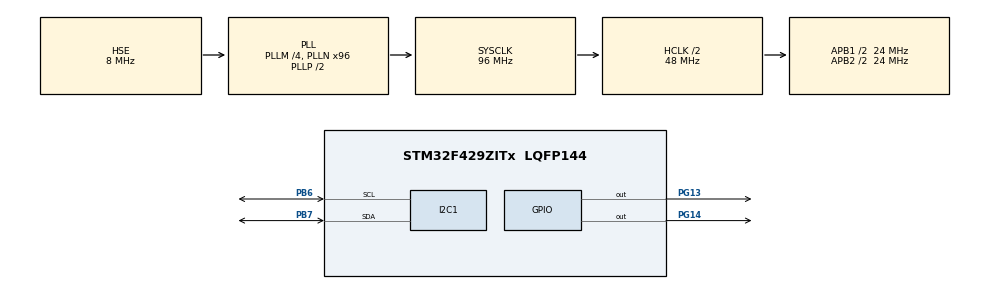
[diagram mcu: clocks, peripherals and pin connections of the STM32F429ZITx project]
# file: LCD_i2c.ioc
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Mcu.Family=STM32F4
Mcu.Name=STM32F429ZITx
Mcu.Package=LQFP144
NVIC.PriorityGroup=NVIC_PRIORITYGROUP_0
NVIC.TIM3_IRQn=true\:0\:0\:false\:false\:true\:true\:true\:true
NVIC.TIM4_IRQn=true\:0\:0\:false\:false\:true\:true\:true\:true
PA13.Mode=Serial_Wire
PA13.Signal=SYS_JTMS-SWDIO
PA14.Mode=Serial_Wire
PA14.Signal=SYS_JTCK-SWCLK
PB6.GPIO_Pu=GPIO_NOPULL
PB6.GPIO_Speed=GPIO_SPEED_FREQ_HIGH
PB6.Mode=I2C
PB6.Signal=I2C1_SCL
PB7.GPIO_Pu=GPIO_NOPULL
PB7.GPIO_Speed=GPIO_SPEED_FREQ_HIGH
PB7.Mode=I2C
PB7.Signal=I2C1_SDA
PG13.PinState=GPIO_PIN_SET
PG13.Signal=GPIO_Output
PG14.Signal=GPIO_Output
PH0/OSC_IN.Mode=HSE-External-Oscillator
PH0/OSC_IN.Signal=RCC_OSC_IN
PH1/OSC_OUT.Mode=HSE-External-Oscillator
PH1/OSC_OUT.Signal=RCC_OSC_OUT
ProjectManager.HeapSize=0x200
ProjectManager.StackSize=0x400
ProjectManager.TargetToolchain=Makefile
RCC.48MHZClocksFreq_Value=64000000
RCC.AHBCLKDivider=RCC_SYSCLK_DIV2
RCC.AHBFreq_Value=48000000
RCC.APB1CLKDivider=RCC_HCLK_DIV2
RCC.APB1Freq_Value=24000000
RCC.APB1TimFreq_Value=48000000
RCC.APB2CLKDivider=RCC_HCLK_DIV2
RCC.APB2Freq_Value=24000000
RCC.APB2TimFreq_Value=48000000
RCC.CortexFreq_Value=48000000
RCC.HCLKFreq_Value=48000000
RCC.HSE_VALUE=8000000
RCC.HSI_VALUE=16000000
RCC.LSE_VALUE=32768
RCC.PLLM=4
RCC.PLLN=96
RCC.PLLQ=3
RCC.PLLSourceVirtual=RCC_PLLSOURCE_HSE
RCC.RCC_TIM_PRescaler_Selection=RCC_TIMPRES_DESACTIVATED
RCC.SYSCLKFreq_VALUE=96000000
RCC.SYSCLKSource=RCC_SYSCLKSOURCE_PLLCLK
RCC.VCOOutputFreq_Value=192000000
TIM3.ClockDivision=TIM_CLOCKDIVISION_DIV4
TIM3.Period=99
TIM3.Prescaler=199
TIM4.ClockDivision=TIM_CLOCKDIVISION_DIV4
TIM4.Period=999
TIM4.Prescaler=199
VP_TIM3_VS_ClockSourceINT.Mode=Internal
VP_TIM4_VS_ClockSourceINT.Mode=Internal
board=STM32F429I-DISC1

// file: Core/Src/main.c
/* USER CODE BEGIN Header */
/**
  ******************************************************************************
  * @file           : main.c
  * @brief          : Main program body
  ******************************************************************************
  * @attention
  *
  * Copyright (c) 2024 STMicroelectronics.
  * All rights reserved.
  *
  * This software is licensed under terms that can be found in the LICENSE file
  * in the root directory of this software component.
  * If no LICENSE file comes with this software, it is provided AS-IS.
  *
  ******************************************************************************
  */
/* USER CODE END Header */
#include "main.h"
#include "i2c.h"
#include "tim.h"
#include "gpio.h"

/* USER CODE BEGIN Includes */
#include "lcd.h"
/* USER CODE END Includes */

void SystemClock_Config(void);

int main(void)
{

  /* MCU Configuration--------------------------------------------------------*/

  /* Reset of all peripherals, Initializes the Flash interface and the Systick. */
  HAL_Init();

  /* Configure the system clock */
  SystemClock_Config();

  /* Initialize all configured peripherals */
  MX_GPIO_Init();
  MX_TIM3_Init();
  MX_TIM4_Init();
  MX_I2C1_Init();
  /* USER CODE BEGIN 2 */
  LCDInit();
  LCDSendString("HELLO WORLD",0,0);
  LCDSendString("Test 1234",1,0);
  LCDSendString("______",2,0);
  LCDSendString("+++++++",3,0);
  /* USER CODE END 2 */

  /* Infinite loop */
  while (1)
  {

  }
}

void SystemClock_Config(void)
{
  RCC_OscInitTypeDef RCC_OscInitStruct = {0};
  RCC_ClkInitTypeDef RCC_ClkInitStruct = {0};

  /** Configure the main internal regulator output voltage
  */
  __HAL_RCC_PWR_CLK_ENABLE();
  __HAL_PWR_VOLTAGESCALING_CONFIG(PWR_REGULATOR_VOLTAGE_SCALE3);

  /** Initializes the RCC Oscillators according to the specified parameters
  * in the RCC_OscInitTypeDef structure.
  */
  RCC_OscInitStruct.OscillatorType = RCC_OSCILLATORTYPE_HSE;
  RCC_OscInitStruct.HSEState = RCC_HSE_ON;
  RCC_OscInitStruct.PLL.PLLState = RCC_PLL_ON;
  RCC_OscInitStruct.PLL.PLLSource = RCC_PLLSOURCE_HSE;
  RCC_OscInitStruct.PLL.PLLM = 4;
  RCC_OscInitStruct.PLL.PLLN = 96;
  RCC_OscInitStruct.PLL.PLLP = RCC_PLLP_DIV2;
  RCC_OscInitStruct.PLL.PLLQ = 3;
  if (HAL_RCC_OscConfig(&RCC_OscInitStruct) != HAL_OK)
  {
    Error_Handler();
  }

  /** Initializes the CPU, AHB and APB buses clocks
  */
  RCC_ClkInitStruct.ClockType = RCC_CLOCKTYPE_HCLK|RCC_CLOCKTYPE_SYSCLK
                              |RCC_CLOCKTYPE_PCLK1|RCC_CLOCKTYPE_PCLK2;
  RCC_ClkInitStruct.SYSCLKSource = RCC_SYSCLKSOURCE_PLLCLK;
  RCC_ClkInitStruct.AHBCLKDivider = RCC_SYSCLK_DIV2;
  RCC_ClkInitStruct.APB1CLKDivider = RCC_HCLK_DIV2;
  RCC_ClkInitStruct.APB2CLKDivider = RCC_HCLK_DIV2;

  if (HAL_RCC_ClockConfig(&RCC_ClkInitStruct, FLASH_LATENCY_1) != HAL_OK)
  {
    Error_Handler();
  }
}

void Error_Handler(void)
{
  __disable_irq();
  while (1)
  {
  }
}
